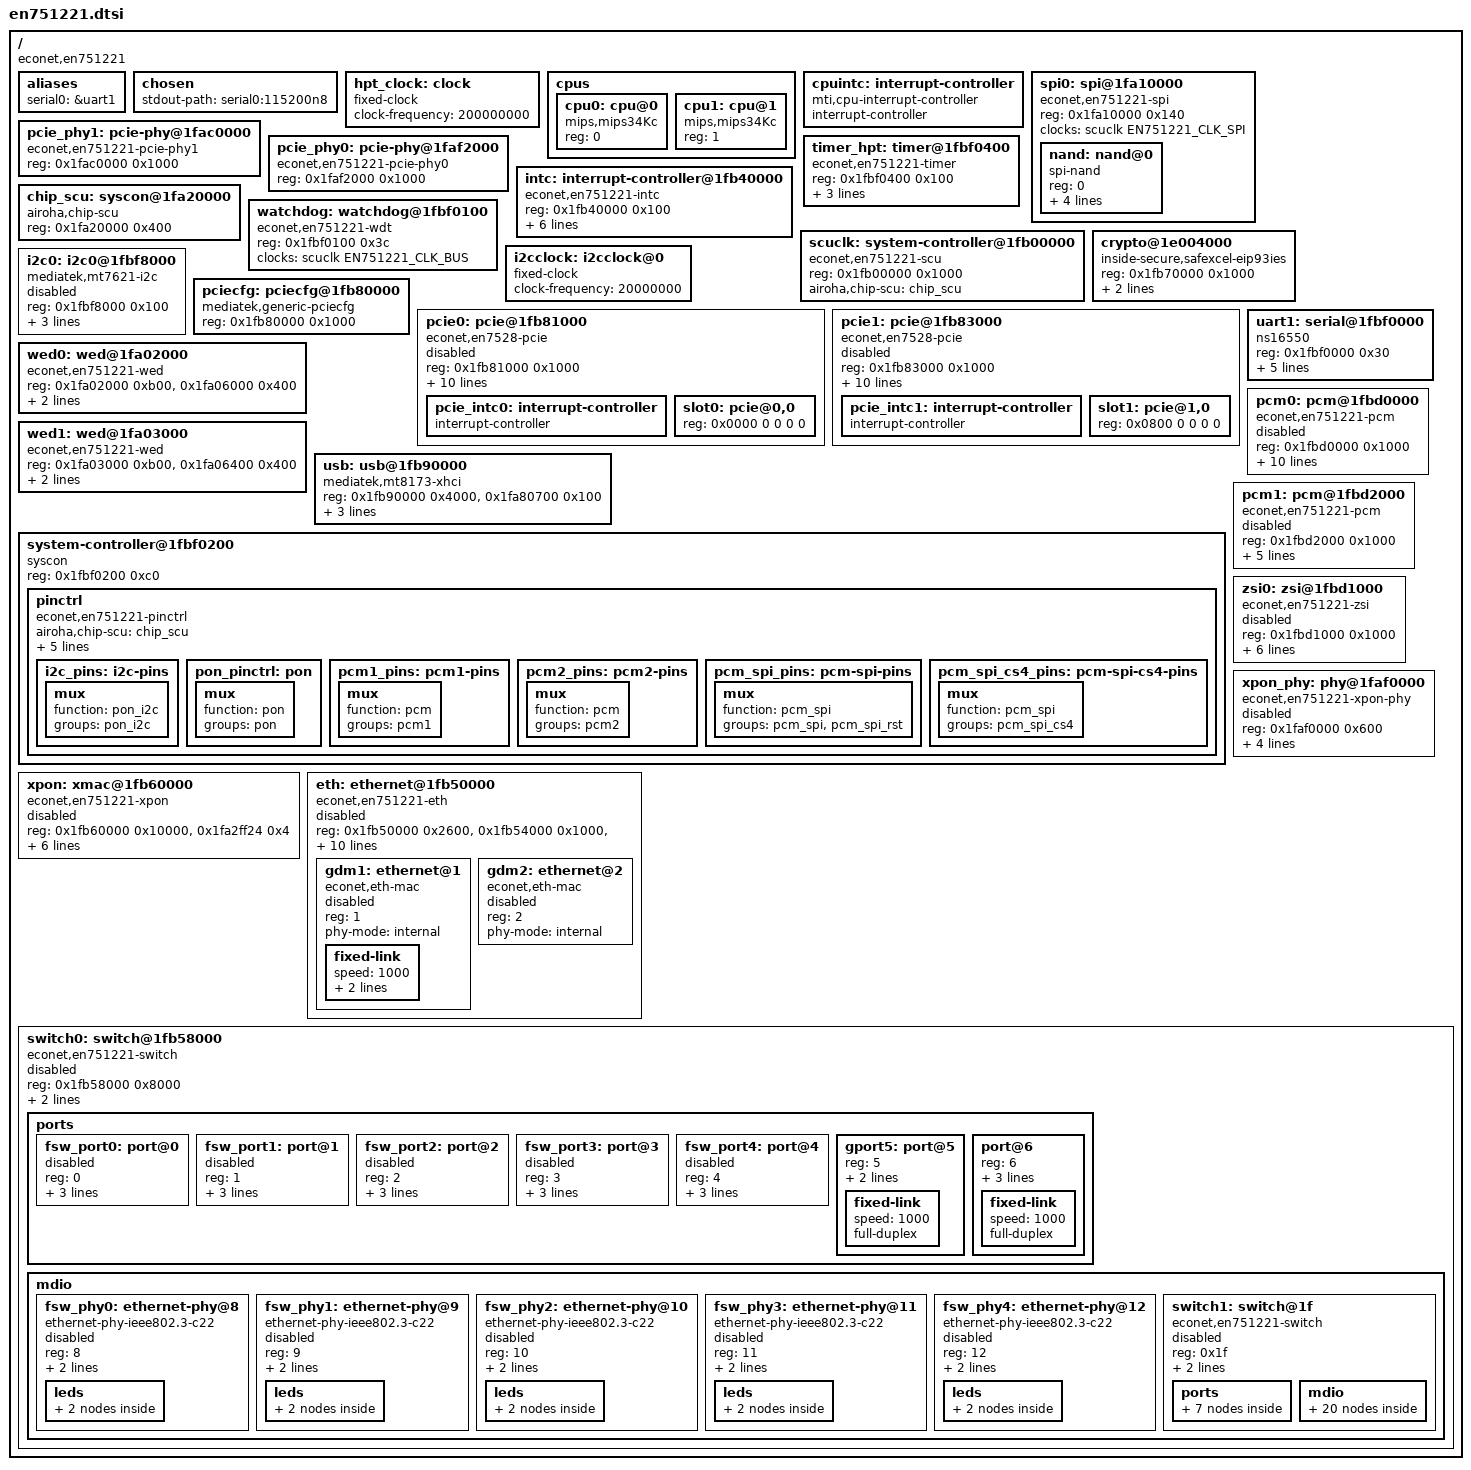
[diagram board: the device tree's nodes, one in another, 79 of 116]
// SPDX-License-Identifier: (GPL-2.0-only OR BSD-2-Clause)

#include <dt-bindings/reset/econet,en751221-scu.h>
#include <dt-bindings/clock/econet,en751221-scu.h>
#include <dt-bindings/leds/common.h>
#include <dt-bindings/gpio/gpio.h>
#include <dt-bindings/input/input.h>
#include <dt-bindings/soc/airoha,scu-ssr.h>
#include <dt-bindings/thermal/thermal.h>
#include <dt-bindings/phy/phy.h>
#include <dt-bindings/soc/airoha,soc-variant.h>

/dts-v1/;

/ {
	compatible = "econet,en751221";
	#address-cells = <1>;
	#size-cells = <1>;

	aliases {
		serial0 = &uart1;
	};

	chosen {
		stdout-path = "serial0:115200n8";
	};
	
	hpt_clock: clock {
		compatible = "fixed-clock";
		#clock-cells = <0>;
		clock-frequency = <200000000>;  /* 200 MHz */
	};

	cpus: cpus {
		#address-cells = <1>;
		#size-cells = <0>;

		cpu0: cpu@0 {
			device_type = "cpu";
			compatible = "mips,mips34Kc";
			reg = <0>;
		};

		cpu1: cpu@1 {
			device_type = "cpu";
			compatible = "mips,mips34Kc";
			reg = <1>;
		};
	};

	cpuintc: interrupt-controller {
		compatible = "mti,cpu-interrupt-controller";
		interrupt-controller;
		#address-cells = <0>;
		#interrupt-cells = <1>;
	};

	spi0: spi@1fa10000 {
		compatible = "econet,en751221-spi";
		reg = <0x1fa10000 0x140>;

		clocks = <&scuclk EN751221_CLK_SPI>;
		clock-names = "spi";
		#address-cells = <1>;
		#size-cells = <0>;

		nand: nand@0 {
			compatible = "spi-nand";
			reg = <0>;
			spi-max-frequency = <25000000>;
			spi-rx-bus-width = <2>;
			spi-tx-bus-width = <1>;
			nand-ecc-engine = <&nand>;
		};
	};

	pcie_phy1: pcie-phy@1fac0000 {
		compatible = "econet,en751221-pcie-phy1";
		reg = <0x1fac0000 0x1000>;
		#phy-cells = <0>;
	};

	pcie_phy0: pcie-phy@1faf2000 {
		compatible = "econet,en751221-pcie-phy0";
		reg = <0x1faf2000 0x1000>;
		#phy-cells = <0>;
	};

	intc: interrupt-controller@1fb40000 {
		compatible = "econet,en751221-intc";
		reg = <0x1fb40000 0x100>;
		interrupt-parent = <&cpuintc>;
		interrupts = <2>;

		interrupt-controller;
		#interrupt-cells = <1>;
		econet,shadow-interrupts = <7 2>, <8 3>, <13 12>, <30 29>;
		econet,cpu-interrupt-map = <7 0>, <8 1>;
	};

	timer_hpt: timer@1fbf0400 {
		compatible = "econet,en751221-timer";
		reg = <0x1fbf0400 0x100>;

		interrupt-parent = <&intc>;
		interrupts = <30>;
		clocks = <&hpt_clock>;
	};

	chip_scu: syscon@1fa20000 {
		compatible = "airoha,chip-scu", "syscon";
		reg = <0x1fa20000 0x400>;
	};

	scuclk: system-controller@1fb00000 {
		compatible = "econet,en751221-scu", "syscon";
		reg = <0x1fb00000 0x1000>;
		airoha,chip-scu = <&chip_scu>;

		#clock-cells = <1>;
		#reset-cells = <1>;
	};

	watchdog: watchdog@1fbf0100 {
		compatible = "econet,en751221-wdt";
		reg = <0x1fbf0100 0x3c>;

		clocks = <&scuclk EN751221_CLK_BUS>;
		clock-names = "bus";
	};

	crypto@1e004000 {
		compatible = "inside-secure,safexcel-eip93ies";
		reg = <0x1fb70000 0x1000>;

		interrupt-parent = <&intc>;
		interrupts = <28>;
	};

	i2cclock: i2cclock@0 {
		#clock-cells = <0>;
		compatible = "fixed-clock";

		/* 20 MHz */
		clock-frequency = <20000000>;
	};

	i2c0: i2c0@1fbf8000 {
		// compatible = "airoha,en7523-i2c";
		compatible = "mediatek,mt7621-i2c";
		reg = <0x1fbf8000 0x100>;

		clocks = <&i2cclock>;
		pinctrl-names = "default";
		pinctrl-0 = <&i2c_pins>;

		/* 100 kHz */
		clock-frequency = <100000>;
		#address-cells = <1>;
		#size-cells = <0>;

		status = "disabled";
	};

	pciecfg: pciecfg@1fb80000 {
		compatible = "mediatek,generic-pciecfg", "syscon";
		reg = <0x1fb80000 0x1000>;
	};

	pcie0: pcie@1fb81000 {
		compatible = "econet,en7528-pcie";
		device_type = "pci";
		reg = <0x1fb81000 0x1000>;
		reg-names = "port0";
		linux,pci-domain = <0>;
		#address-cells = <3>;
		#size-cells = <2>;
		interrupt-parent = <&intc>;
		interrupts = <23>;
		interrupt-names = "pcie_irq";
		clocks = <&scuclk EN751221_CLK_PCIE>;
		clock-names = "sys_ck0";
		phys = <&pcie_phy0>;
		phy-names = "pcie-phy0";
		bus-range = <0x00 0xff>;
		ranges = <0x01000000 0 0x00000000 0x1f600000 0 0x00008000>,
			 <0x82000000 0 0x20000000 0x20000000 0 0x08000000>;
		status = "disabled";

		#interrupt-cells = <1>;
		interrupt-map-mask = <0 0 0 7>;
		interrupt-map = <0 0 0 1 &pcie_intc0 0>,
				<0 0 0 2 &pcie_intc0 1>,
				<0 0 0 3 &pcie_intc0 2>,
				<0 0 0 4 &pcie_intc0 3>;

		pcie_intc0: interrupt-controller {
			interrupt-controller;
			#address-cells = <0>;
			#interrupt-cells = <1>;
		};

		slot0: pcie@0,0 {
			reg = <0x0000 0 0 0 0>;
			device_type = "pci";
			#address-cells = <3>;
			#size-cells = <2>;
			ranges;
		};
	};

	pcie1: pcie@1fb83000 {
		compatible = "econet,en7528-pcie";
		device_type = "pci";
		reg = <0x1fb83000 0x1000>;
		reg-names = "port1";
		linux,pci-domain = <1>;
		#address-cells = <3>;
		#size-cells = <2>;
		interrupt-parent = <&intc>;
		interrupts = <24>;
		interrupt-names = "pcie_irq";
		clocks = <&scuclk EN751221_CLK_PCIE>;
		clock-names = "sys_ck1";
		phys = <&pcie_phy1>;
		phy-names = "pcie-phy1";
		bus-range = <0x00 0xff>;
		ranges = <0x81000000 0 0x00000000 0x1f608000 0 0x00008000>,
			 <0x82000000 0 0x28000000 0x28000000 0 0x08000000>;
		status = "disabled";

		#interrupt-cells = <1>;
		interrupt-map-mask = <0 0 0 7>;
		interrupt-map = <0 0 0 1 &pcie_intc1 0>,
				<0 0 0 2 &pcie_intc1 1>,
				<0 0 0 3 &pcie_intc1 2>,
				<0 0 0 4 &pcie_intc1 3>;

		pcie_intc1: interrupt-controller {
			interrupt-controller;
			#address-cells = <0>;
			#interrupt-cells = <1>;
		};

		slot1: pcie@1,0 {
			reg = <0x0800 0 0 0 0>;
			#address-cells = <3>;
			#size-cells = <2>;
			ranges;
		};
	};

	wed0: wed@1fa02000 {
		compatible = "econet,en751221-wed", "syscon";
		reg = <0x1fa02000 0xb00>,
		      <0x1fa06000 0x400>;
		reg-names = "wed", "wdma";
		interrupt-parent = <&intc>;
		interrupts = <51>;
	};

	wed1: wed@1fa03000 {
		compatible = "econet,en751221-wed", "syscon";
		reg = <0x1fa03000 0xb00>,
		      <0x1fa06400 0x400>;
		reg-names = "wed", "wdma";
		interrupt-parent = <&intc>;
		interrupts = <52>;
	};

	usb: usb@1fb90000 {
		compatible = "mediatek,mt8173-xhci", "mediatek,mtk-xhci";
		reg = <0x1fb90000 0x4000>,
		      <0x1fa80700 0x100>;
		reg-names = "mac", "ippc";

		#address-cells = <1>;
		#size-cells = <0>;

		interrupt-parent = <&intc>;
		interrupts = <17>;
		usb3-lpm-capable;
	};

	uart1: serial@1fbf0000 {
		compatible = "ns16550";
		reg = <0x1fbf0000 0x30>;
		reg-io-width = <4>;
		reg-shift = <2>;
		interrupt-parent = <&intc>;
		interrupts = <0>;
		/*
		 * Conversion of baud rate to clock frequency requires a
		 * computation that is not in the ns16550 driver, so this
		 * uart is fixed at 115200 baud.
		 */
		clock-frequency = <1843200>;
	};

	system-controller@1fbf0200 {
		compatible = "syscon", "simple-mfd";
		reg = <0x1fbf0200 0xc0>;

		pinctrl: pinctrl {
			compatible = "econet,en751221-pinctrl";
			airoha,chip-scu = <&chip_scu>;

			interrupt-parent = <&intc>;
			interrupts = <10>;

			gpio-controller;
			#gpio-cells = <2>;
			gpio-ranges = <&pinctrl 0 13 31>;

			interrupt-controller;
			#interrupt-cells = <2>;

			i2c_pins: i2c-pins {
				mux {
					function = "pon_i2c";
					groups = "pon_i2c";
				};
			};

			pon_pinctrl: pon {
				mux {
					function = "pon";
					groups = "pon";
				};
			};

			/*
			 * PCM/ZSI pin groups. Every PCM mux bit lives in
			 * chip_scu + 0x0104 (REG_IOMUX_CONTROL1): pcm1
			 * gpio 25-28 bit 13, pcm2 gpio 17-20 bit 14,
			 * pcm_spi gpio 17-20 bit 12 (SPI2_MODE), pcm_spi_int
			 * gpio 16 bit 11, pcm_spi_rst gpio 15 bit 10,
			 * pcm_spi_cs4 gpio 22 bit 9, pcm_spi_cs3 gpio 16
			 * bit 8. "pcm_spi" occupies the same four pins as
			 * "pcm2", so a board using the multiplexed SLIC
			 * control channel gives up the second PCM bus.
			 * pcm_spi_int and pcm_spi_cs3 are both gpio 16 --
			 * pick one.
			 */
			pcm1_pins: pcm1-pins {
				mux {
					function = "pcm";
					groups = "pcm1";
				};
			};

			pcm2_pins: pcm2-pins {
				mux {
					function = "pcm";
					groups = "pcm2";
				};
			};

			/* PCM bus 2 pins carrying the multiplexed SLIC control channel */
			pcm_spi_pins: pcm-spi-pins {
				mux {
					function = "pcm_spi";
					groups = "pcm_spi", "pcm_spi_rst";
				};
			};

			pcm_spi_cs4_pins: pcm-spi-cs4-pins {
				mux {
					function = "pcm_spi";
					groups = "pcm_spi_cs4";
				};
			};
		};
	};

	pcm0: pcm@1fbd0000 {
		compatible = "econet,en751221-pcm";
		reg = <0x1fbd0000 0x1000>;
		reg-names = "pcm";

		/* PCM1 input in the EN751221 interrupt controller. */
		interrupt-parent = <&intc>;
		interrupts = <11>;

		resets = <&scuclk EN751221_PCM1_RST>;
		reset-names = "pcm";

		pinctrl-names = "default";
		pinctrl-0 = <&pcm1_pins>;

		/* read back from stock firmware; see pcm_asterisk docs/01 */
		airoha,pcm-interface-control = <0xf5071306>;

		/*
		 * 16-bit slots at bit offsets 32, 48, 64, 80, 96, 112,
		 * 128, 144. Two slots per register; low half is the even
		 * slot, high half the odd one.
		 */
		airoha,tx-slot-config = <0x10301020 0x10501040
					 0x10701060 0x10901080>;
		airoha,rx-slot-config = <0x10301020 0x10501040
					 0x10701060 0x10901080>;
		airoha,dma-channel-mask = <0xff>;

		status = "disabled";
	};

	/* Second PCM instance. Present in silicon; rarely wired up. */
	pcm1: pcm@1fbd2000 {
		compatible = "econet,en751221-pcm";
		reg = <0x1fbd2000 0x1000>;
		reg-names = "pcm";
		/* PCM2 input; hwirq 33 is in the controller's second bank. */
		interrupt-parent = <&intc>;
		interrupts = <33>;
		resets = <&scuclk EN751221_PCM2_RST>;
		reset-names = "pcm";
		pinctrl-names = "default";
		pinctrl-0 = <&pcm2_pins>;
		airoha,pcm-interface-control = <0xf5071306>;
		status = "disabled";
	};

	/*
	 * ZSI: the SLIC control channel multiplexed over the PCM bus.
	 * It rides the pcm2 pins, so a board that enables this cannot
	 * also mux pcm2 on pcm1 above.
	 */
	zsi0: zsi@1fbd1000 {
		compatible = "econet,en751221-zsi";
		reg = <0x1fbd1000 0x1000>;
		reg-names = "zsi";

		airoha,scu = <&scuclk>;
		airoha,chip-scu = <&chip_scu>;
		resets = <&scuclk EN751221_PCM1_ZSI_ISI_RST>;
		reset-names = "zsi";

		/*
		 * Temporary compatibility path: the current MIPS clock provider
		 * has no SLIC clock. These raw offsets are verified on EN751221
		 * only and the driver rejects this property on other SoCs.
		 */
		airoha,legacy-scu-programming;

		pinctrl-names = "default";
		pinctrl-0 = <&pcm_spi_pins>;

		#address-cells = <1>;
		#size-cells = <0>;

		/*
		 * Inter-byte gap. The wrapper acknowledges a byte as soon
		 * as it has sent it, but the SLIC still has to clock it
		 * over the 8 kHz bus. Below about 2000 us the SLIC
		 * mis-parses profile streams.
		 */
		airoha,zsi-gap-us = <5000>;

		status = "disabled";
	};

	xpon_phy: phy@1faf0000 {
		compatible = "econet,en751221-xpon-phy";
		// reg = <0x1faf0000 0x5000>;
		reg = <0x1faf0000 0x600>;

		pinctrl-names = "default";
		pinctrl-0 = <&pon_pinctrl>;

		resets = <&scuclk EN751221_XPON_PHY_RST>;
		reset-names = "phy";

		airoha,scu = <&scuclk>;
		airoha,chip-scu = <&chip_scu>;

		#phy-cells = <0>;

		status = "disabled";
	};

	xpon: xmac@1fb60000 {
		compatible = "econet,en751221-xpon";

		reg = <0x1fb60000 0x10000>,
		      <0x1fa2ff24 0x4>;
		reg-names = "mac", "tx-off";

		interrupt-parent = <&intc>;
		interrupts = <18>;
		interrupt-names = "dying-gasp";

		resets = <&scuclk EN751221_XPON_MAC_RST>;
		reset-names = "mac";

		phys = <&xpon_phy>;
		phy-names = "xpon";

		ethernet = <&gdm2>;
		airoha,scu = <&scuclk>;

		status = "disabled";
	};

	eth: ethernet@1fb50000 {
		compatible = "econet,en751221-eth";
		status = "disabled";
		reg = <0x1fb50000 0x2600>,
		      <0x1fb54000 0x1000>,
		      <0x1fb55000 0x1000>,
		      <0x1fbf9000 0x1000>;
		reg-names = "fe", "qdma0", "qdma1", "gdmp";

		interrupt-parent = <&intc>;
		interrupts = <21>, <22>;
		interrupt-names = "qdma0", "qdma1";
		airoha,wed = <&wed0>, <&wed1>;

		resets = <&scuclk EN751221_FE_RST>,
		         <&scuclk EN751221_FE_QDMA1_RST>,
		         <&scuclk EN751221_FE_QDMA2_RST>,
		         <&scuclk EN751221_GDMA_RST>,
		         <&scuclk EN751221_FE_UNZIP_RST>,
		         <&scuclk EN751221_GDMP_RST>;
		reset-names = "fe", "pdma", "qdma", /* rename to pdma, qdma */
		              "gdma", "fe-unzip", "gdmp";

		#address-cells = <1>;
		#size-cells = <0>;

		gdm1: ethernet@1 {
			compatible = "econet,eth-mac";
			reg = <1>;
			phy-mode = "internal";
			status = "disabled";

			fixed-link {
				speed = <1000>;
				full-duplex;
				pause;
			};
		};

		gdm2: ethernet@2 {
			compatible = "econet,eth-mac";
			reg = <2>;
			phy-mode = "internal";
			status = "disabled";
		};
	};

	switch0: switch@1fb58000 {
		compatible = "econet,en751221-switch";
		reg = <0x1fb58000 0x8000>;
		resets = <&scuclk EN751221_GSW_RST>;

		status = "disabled";

		#address-cells = <1>;
		#size-cells = <0>;
		dsa,member = <0 0>;

		ports {
			#address-cells = <1>;
			#size-cells = <0>;

			fsw_port0: port@0 {
				reg = <0>;
				phy-mode = "internal";
				phy-handle = <&fsw_phy0>;
				status = "disabled";
				label = "lan1";
			};

			fsw_port1: port@1 {
				reg = <1>;
				phy-mode = "internal";
				phy-handle = <&fsw_phy1>;
				status = "disabled";
				label = "lan2";
			};

			fsw_port2: port@2 {
				reg = <2>;
				phy-mode = "internal";
				phy-handle = <&fsw_phy2>;
				status = "disabled";
				label = "lan3";
			};

			fsw_port3: port@3 {
				reg = <3>;
				phy-mode = "internal";
				phy-handle = <&fsw_phy3>;
				status = "disabled";
				label = "lan4";
			};

			fsw_port4: port@4 {
				reg = <4>;
				phy-mode = "internal";
				phy-handle = <&fsw_phy4>;
				status = "disabled";
				label = "lan5";
			};

			gport5: port@5 {
				reg = <5>;
				phy-mode = "trgmii";
				link = <&mcm_port6>;

				fixed-link {
					speed = <1000>;
					full-duplex;
				};
			};

			port@6 {
				reg = <6>;
				label = "cpu";
				ethernet = <&gdm1>;
				phy-mode = "internal";

				fixed-link {
					speed = <1000>;
					full-duplex;
				};
			};
		};

		mdio: mdio {
			#address-cells = <1>;
			#size-cells = <0>;

			fsw_phy0: ethernet-phy@8 {
				compatible = "ethernet-phy-ieee802.3-c22";
				reg = <8>;
				phy-mode = "internal";
				status = "disabled";

				airoha,scu = <&scuclk>;

				leds {
					led@0 {
						reg = <0>;
						function = LED_FUNCTION_LAN;
						active-low;
					};

					led@1 {
						reg = <1>;
						function = LED_FUNCTION_ACTIVITY;
						status = "disabled";
						active-low;
					};
				};
			};

			fsw_phy1: ethernet-phy@9 {
				compatible = "ethernet-phy-ieee802.3-c22";
				reg = <9>;
				phy-mode = "internal";
				status = "disabled";

				airoha,scu = <&scuclk>;

				leds {
					led@0 {
						reg = <0>;
						function = LED_FUNCTION_LAN;
						active-low;
					};

					led@1 {
						reg = <1>;
						function = LED_FUNCTION_ACTIVITY;
						status = "disabled";
						active-low;
					};
				};
			};

			fsw_phy2: ethernet-phy@10 {
				compatible = "ethernet-phy-ieee802.3-c22";
				reg = <10>;
				phy-mode = "internal";
				status = "disabled";

				airoha,scu = <&scuclk>;

				leds {
					led@0 {
						reg = <0>;
						function = LED_FUNCTION_LAN;
						active-low;
					};

					led@1 {
						reg = <1>;
						function = LED_FUNCTION_ACTIVITY;
						status = "disabled";
						active-low;
					};
				};
			};

			fsw_phy3: ethernet-phy@11 {
				compatible = "ethernet-phy-ieee802.3-c22";
				reg = <11>;
				phy-mode = "internal";
				status = "disabled";

				airoha,scu = <&scuclk>;

				leds {
					led@0 {
						reg = <0>;
						function = LED_FUNCTION_LAN;
						active-low;
					};

					led@1 {
						reg = <1>;
						function = LED_FUNCTION_ACTIVITY;
						status = "disabled";
						active-low;
					};
				};
			};

			fsw_phy4: ethernet-phy@12 {
				compatible = "ethernet-phy-ieee802.3-c22";
				reg = <12>;
				phy-mode = "internal";
				status = "disabled";

				airoha,scu = <&scuclk>;

				leds {
					led@0 {
						reg = <0>;
						function = LED_FUNCTION_LAN;
						active-low;
					};

					led@1 {
						reg = <1>;
						function = LED_FUNCTION_ACTIVITY;
						status = "disabled";
						active-low;
					};
				};
			};

			switch1: switch@1f {
				compatible = "econet,en751221-switch";
				reg = <0x1f>;
				mediatek,mcm;
				dsa,member = <0 1>;
				status = "disabled";

				#address-cells = <1>;
				#size-cells = <0>;

				ports {
					#address-cells = <1>;
					#size-cells = <0>;

					gsw_port0: port@0 {
						reg = <0>;
						phy-mode = "gmii";
						phy-handle = <&gsw_phy0>;
						status = "disabled";
						label = "lan1";
					};

					gsw_port1: port@1 {
						reg = <1>;
						phy-mode = "gmii";
						phy-handle = <&gsw_phy1>;
						status = "disabled";
						label = "lan2";
					};

					gsw_port2: port@2 {
						reg = <2>;
						phy-mode = "gmii";
						phy-handle = <&gsw_phy2>;
						status = "disabled";
						label = "lan3";
					};

					gsw_port3: port@3 {
						reg = <3>;
						phy-mode = "gmii";
						phy-handle = <&gsw_phy3>;
						status = "disabled";
						label = "lan4";
					};

					gsw_port4: port@4 {
						reg = <4>;
						phy-mode = "gmii";
						phy-handle = <&gsw_phy4>;
						status = "disabled";
						label = "lan5";
					};

					mcm_port6: port@6 {
						reg = <6>;
						phy-mode = "trgmii";
						link = <&gport5>;

						fixed-link {
							speed = <1000>;
							full-duplex;
						};
					};
				};

				mdio {
					#address-cells = <1>;
					#size-cells = <0>;

					gsw_phy0: ethernet-phy@0 {
						compatible = "ethernet-phy-ieee802.3-c22";
						reg = <0>;

						airoha,scu = <&scuclk>;

						leds {
							led@0 {
								reg = <0>;
								function = LED_FUNCTION_LAN;
								status = "disabled";
								active-low;
							};

							led@1 {
								reg = <1>;
								function = LED_FUNCTION_ACTIVITY;
								status = "disabled";
								active-low;
							};
						};
					};

					gsw_phy1: ethernet-phy@1 {
						compatible = "ethernet-phy-ieee802.3-c22";
						reg = <1>;

						airoha,scu = <&scuclk>;

						leds {
							led@0 {
								reg = <0>;
								function = LED_FUNCTION_LAN;
								status = "disabled";
								active-low;
							};

							led@1 {
								reg = <1>;
								function = LED_FUNCTION_ACTIVITY;
								status = "disabled";
								active-low;
							};
						};
					};

					gsw_phy2: ethernet-phy@2 {
						compatible = "ethernet-phy-ieee802.3-c22";
						reg = <2>;

						airoha,scu = <&scuclk>;

						leds {
							led@0 {
								reg = <0>;
								function = LED_FUNCTION_LAN;
								status = "disabled";
								active-low;
							};

							led@1 {
								reg = <1>;
								function = LED_FUNCTION_ACTIVITY;
								status = "disabled";
								active-low;
							};
						};
					};

					gsw_phy3: ethernet-phy@3 {
						compatible = "ethernet-phy-ieee802.3-c22";
						reg = <3>;

						airoha,scu = <&scuclk>;

						leds {
							led@0 {
								reg = <0>;
								function = LED_FUNCTION_LAN;
								status = "disabled";
								active-low;
							};

							led@1 {
								reg = <1>;
								function = LED_FUNCTION_ACTIVITY;
								status = "disabled";
								active-low;
							};
						};
					};

					gsw_phy4: ethernet-phy@4 {
						compatible = "ethernet-phy-ieee802.3-c22";
						reg = <4>;

						airoha,scu = <&scuclk>;

						leds {
							led@0 {
								reg = <0>;
								function = LED_FUNCTION_LAN;
								status = "disabled";
								active-low;
							};

							led@1 {
								reg = <1>;
								function = LED_FUNCTION_ACTIVITY;
								status = "disabled";
								active-low;
							};
						};
					};
				};
			};
		};
	};
};
